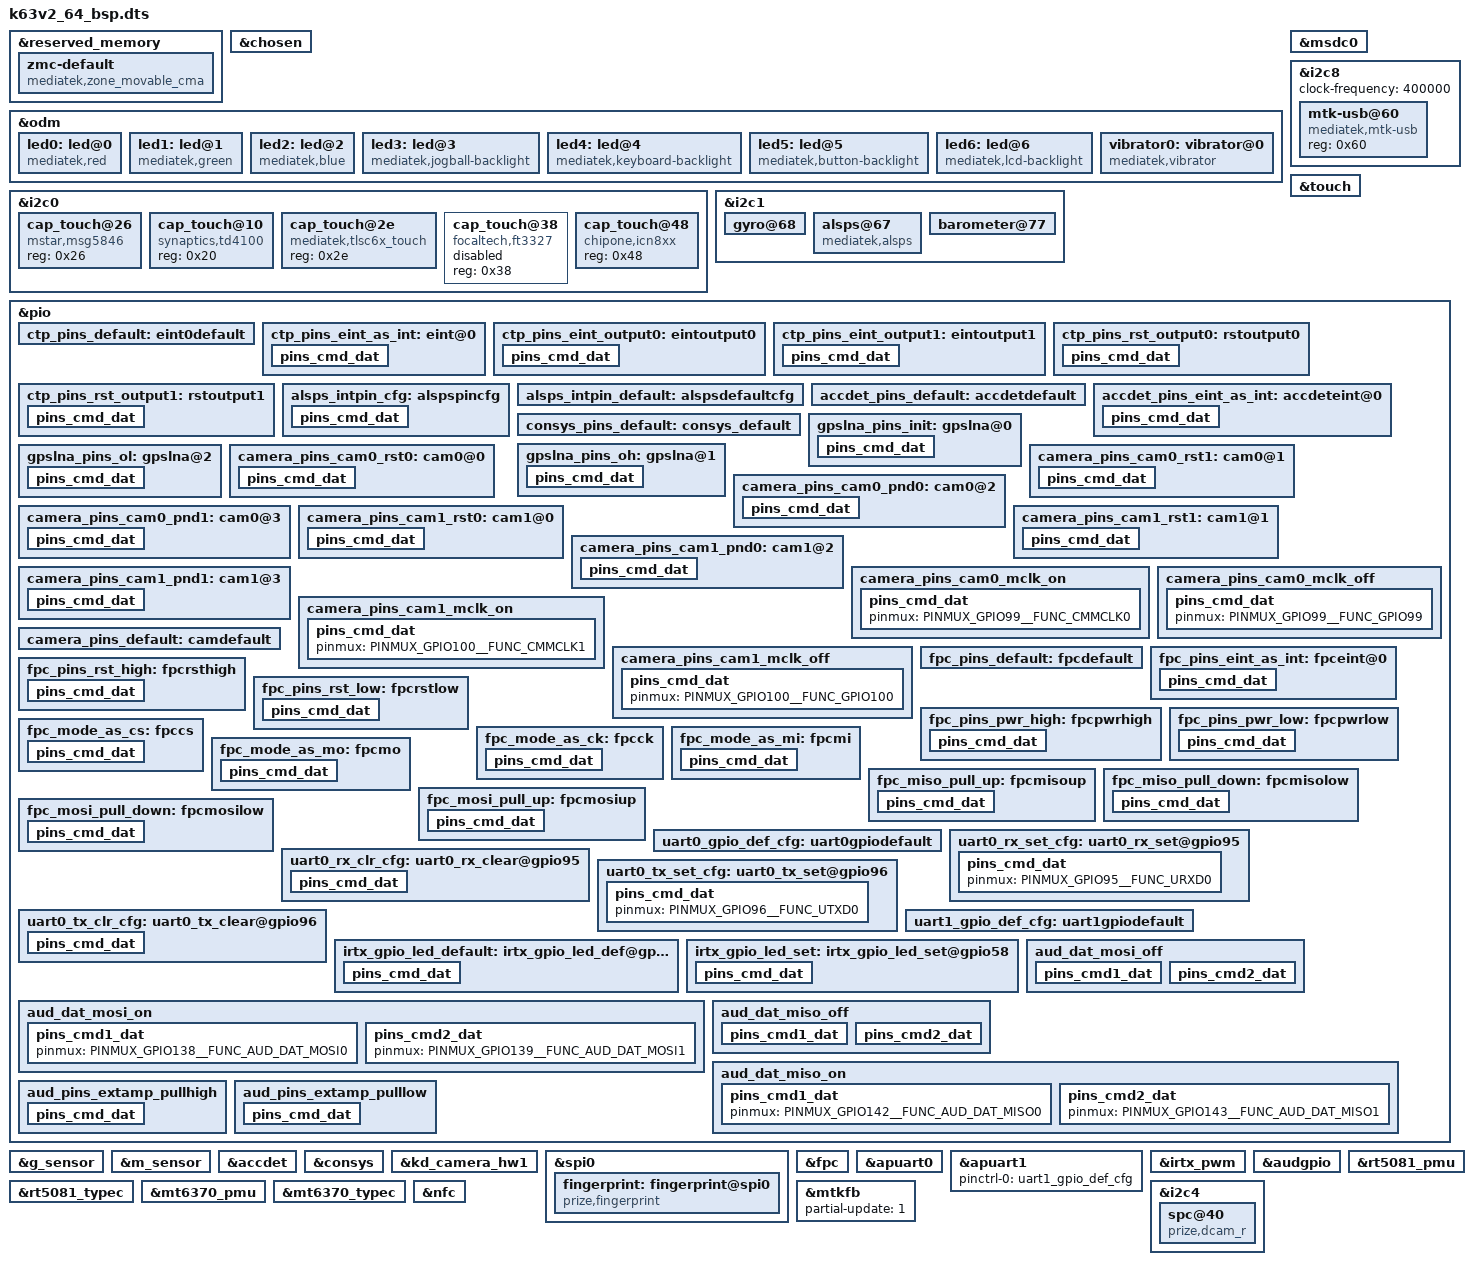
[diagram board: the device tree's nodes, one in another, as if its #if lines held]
/*
 * Mediatek's k63v2_64_bsp SoC device tree source
 *
 * Copyright (C) 2019 MediaTek Inc.
 *
 * This program is free software; you can redistribute it and/or modify
 * it under the terms of the GNU General Public License version 2 as
 * published by the Free Software Foundation.
 *
 * This program is distributed in the hope that it will be useful,
 * but WITHOUT ANY WARRANTY; without even the implied warranty of
 * MERCHANTABILITY or FITNESS FOR A PARTICULAR PURPOSE.
 * See http://www.gnu.org/licenses/gpl-2.0.html for more details.
 */
#include <generated/autoconf.h>
/dts-v1/;

#ifdef CONFIG_MTK_DTBO_FEATURE
/plugin/;
#include <dt-bindings/interrupt-controller/irq.h>
#include <dt-bindings/interrupt-controller/arm-gic.h>
#include <dt-bindings/mmc/mt6763-msdc.h>
#include <dt-bindings/pinctrl/mt6763-pinfunc.h>
#else
#include "mt6763.dts"
#endif



&reserved_memory {
	#address-cells = <2>;
	#size-cells = <2>;
	ranges;

	zmc-default {
		compatible = "mediatek,zone_movable_cma";
		size = <0 0xffc00000>;
		alignment = <0 0x10000000>;
		alloc-ranges = <0 0xc0000000 1 0x00000000>;
	};
};


/* chosen */
&chosen {
	/* fpga may has no lk, we need to specify display info here */
	/* fb buffer is reserved using this dts by memory node above */
	atag,videolfb-fb_base_h = <0x0>;
	atag,videolfb-fb_base_l = <0x5e605000>;
	atag,videolfb-islcmfound = <1>;
	/* because no lk, so lcm is not inited */
	atag,videolfb-islcm_inited = <0>;
	atag,videolfb-fps= <6000>;
	atag,videolfb-vramSize= <0x017bb000>;
	atag,videolfb-lcmname= "nt35695B_fhd_dsi_cmd_auo_rt5081_drv";
};


&odm {
	led0:led@0 {
		compatible = "mediatek,red";
		led_mode = <0>;
		data = <1>;
		pwm_config = <0 0 0 0 0>;
	};
	led1:led@1 {
		compatible = "mediatek,green";
		led_mode = <0>;
		data = <1>;
		pwm_config = <0 0 0 0 0>;
	};
	led2:led@2 {
		compatible = "mediatek,blue";
		led_mode = <0>;
		data = <1>;
		pwm_config = <0 0 0 0 0>;
	};
	led3:led@3 {
		compatible = "mediatek,jogball-backlight";
		led_mode = <0>;
		data = <1>;
		pwm_config = <0 0 0 0 0>;
	};
	led4:led@4 {
		compatible = "mediatek,keyboard-backlight";
		led_mode = <0>;
		data = <1>;
		pwm_config = <0 0 0 0 0>;
	};
	led5:led@5 {
		compatible = "mediatek,button-backlight";
		led_mode = <0>;
		data = <1>;
		pwm_config = <0 0 0 0 0>;
	};
	led6:led@6 {
		compatible = "mediatek,lcd-backlight";
		led_mode = <5>;
		data = <1>;
		pwm_config = <0 3 0 0 0>;
	};
	vibrator0:vibrator@0 {
		compatible = "mediatek,vibrator";
		vib_timer = <25>;
		vib_limit = <9>;
		vib_vol= <9>;
	};
};

&i2c0 {
	cap_touch@26 {
		compatible = "mstar,msg5846";
		reg = <0x26>;
	};
	
	cap_touch@10 {
		compatible = "synaptics,td4100";
		reg = <0x20>;
		status = "okay";
	};

    cap_touch@2e {
        compatible = "mediatek,tlsc6x_touch";
        reg = <0x2e>;  
        status = "okay";
     };
	
	cap_touch@38 {
		compatible = "focaltech,ft3327";
		reg = <0x38>;
		status = "disable"; /* focaltouch drv will auto transform addr, if mediatek,cap_touch exist disable*/
	};
	
	cap_touch@48 {
		compatible = "chipone,icn8xx";
		reg = <0x48>;
	};
	
	//cap_touch@5d {
	//	compatible = "goodix,gt9xx";
	//	reg = <0x5d>;
	//};
};
&i2c1 {
/*  start sensor */
	/*gsensor@68 {
		i2c_num	= <1>;
		direction = <4>;
		power_id = <0xffff>;
		power_vol = <0>;
		firlen = <16>;
		is_batch_supported = <1>;
	};

	msensor@0d {
		i2c_num = <1>;
		i2c_addr = <0x0d 0 0 0>;
		direction = <8>;
		power_id = <0xffff>;
		power_vol = <0>;
		is_batch_supported = <0>;
	};*/

	gyro@68 {
		i2c_num = <1>;
		i2c_addr = <0x68 0 0 0>;
		direction = <4>;
		power_id = <0xffff>;
		power_vol = <0>;
		firlen = <0>;
		is_batch_supported = <0>;
	};

	alsps@67 {
	         compatible = "mediatek,alsps";
		pinctrl-names = "pin_default", "pin_cfg";
		pinctrl-0 = <&alsps_intpin_default>;
		pinctrl-1 = <&alsps_intpin_cfg>;
		status = "okay";
		/* customization */
		i2c_num = <1>;
		i2c_addr = <0x67 0 0 0>;
		polling_mode_ps = <0>;
		polling_mode_als = <1>;
		power_id = <0xffff>;
		power_vol = <0>;
	als_level = <10 50 100 200 400 700 1000 1500 2200 3000 3500 4000 4500 5000 5500>;
	als_value = <0 50 100 200 350 600 1100 1500 2200 3000 4000 6000 8000 10000 20000 20000>;
	ps_threshold_high = <250>;
	ps_threshold_low = <100>;
	is_batch_supported_ps = <0>;
	is_batch_supported_als = <0>;

		 
		



	};

	barometer@77 {
		i2c_num = <1>;
		i2c_addr = <0x77 0 0 0>;
		direction = <0>;
		power_id = <0xffff>;
		power_vol = <0>;
		firlen = <32>;
		is_batch_supported = <0>;
	};
/* end sensor */
};

&msdc0 {
	status = "okay";
};

&i2c8 {
	#address-cells = <1>;
	#size-cells = <0>;
	clock-frequency = <400000>;

	mtk-usb@60 {
		compatible = "mediatek,mtk-usb";
		reg = <0x60>;
		status = "okay";
	};
};

/* TOUCH start */
&touch {
	tpd-resolution = <720 1520>;
	use-tpd-button = <0>;
	tpd-key-num = <3>;
	tpd-key-local= <139 172 158 0>;
	tpd-key-dim-local = <90 883 100 40 230
				 883 100 40 370 883 100 40 0 0 0 0>;
	tpd-max-touch-num = <5>;
	tpd-filter-enable = <0>;
	tpd-filter-pixel-density = <106>;
	tpd-filter-custom-prameters = <0 0 0 0 0 0 0 0 0 0 0 0>;
	tpd-filter-custom-speed = <0 0 0>;
	pinctrl-names = "default", "state_eint_as_int", "state_eint_output0",
		"state_eint_output1", "state_rst_output0", "state_rst_output1";
	pinctrl-0 = <&ctp_pins_default>;
	pinctrl-1 = <&ctp_pins_eint_as_int>;
	pinctrl-2 = <&ctp_pins_eint_output0>;
	pinctrl-3 = <&ctp_pins_eint_output1>;
	pinctrl-4 = <&ctp_pins_rst_output0>;
	pinctrl-5 = <&ctp_pins_rst_output1>;
	status = "okay";
};
&pio {
	ctp_pins_default: eint0default {
	};
	ctp_pins_eint_as_int: eint@0 {
		pins_cmd_dat {
			pinmux = <PINMUX_GPIO1__FUNC_GPIO1>;
			slew-rate = <0>;
			bias-disable;
		};
	};
	ctp_pins_eint_output0: eintoutput0 {
		pins_cmd_dat {
			pinmux = <PINMUX_GPIO1__FUNC_GPIO1>;
			slew-rate = <1>;
			output-low;
		};
	};
	ctp_pins_eint_output1: eintoutput1 {
		pins_cmd_dat {
			pinmux = <PINMUX_GPIO1__FUNC_GPIO1>;
			slew-rate = <1>;
			output-high;
		};
	};
	ctp_pins_rst_output0: rstoutput0 {
		pins_cmd_dat {
			pinmux = <PINMUX_GPIO15__FUNC_GPIO15>;
			slew-rate = <1>;
			output-low;
		};
	};
	ctp_pins_rst_output1: rstoutput1 {
		pins_cmd_dat {
			pinmux = <PINMUX_GPIO15__FUNC_GPIO15>;
			slew-rate = <1>;
			output-high;
		};
	};
};
/* TOUCH end */

&g_sensor {
	i2c_num	= <1>;
	direction = <3>;
	power_id = <0xffff>;
	power_vol = <0>;
	firlen = <16>;
	is_batch_supported = <1>;
};

&m_sensor {
	i2c_num = <1>;
	i2c_addr = <0x0c 0 0 0>;
	direction = <3>;
	power_id = <0xffff>;
	power_vol = <0>;
	is_batch_supported = <0>;
};

/* sensor gpio standization */
&pio {
	alsps_intpin_cfg: alspspincfg {

		pins_cmd_dat {
			pinmux = <PINMUX_GPIO6__FUNC_GPIO6>;
			slew-rate = <0>;
			bias-pull-up = <00>;
		};
	};

	alsps_intpin_default: alspsdefaultcfg {

	};
};
/* sensor end */

/* accdet start */
&accdet {
	/* accdet micbias voltage: 0x07,2.7v;0x05,2.5v;0x02,1.9v */
	accdet-mic-vol = <6>;
	headset-mode-setting = <0x500 0x500 1 0x1f0 0x800 0x800 0x20 0x44>;
	accdet-plugout-debounce = <1>;
	/*1:ACC mode, 2:low cost without in bias, 6:low cost with in bias*/
	accdet-mic-mode = <1>;
	/* eint_level_trigger: 8,LEVEL_LOW(default);4,LEVEL_HIGH;others,*/
	/* LEVEL_LOW */
	headset-eint-level-pol = <8>;
	/*0--MD_MAX--UP_MAX--DW_MAX*/
	headset-three-key-threshold = <0 80 200 400>;
	headset-three-key-threshold-CDD = <0 121 192 600>;
	/*0--MD_MAX--VOICE_MAX--UP_MAX--DW_MAX*/
	headset-four-key-threshold = <0 58 121 192 400>;
	/* ACCDET GPIO standardization ACC mode no use */
	/* interrupt-parent = <&eintc>; */
	/* interrupts = <9 IRQ_TYPE_EDGE_FALLING 9 0>;	*/
	pinctrl-names = "default", "state_eint_as_int";
	pinctrl-0 = <&accdet_pins_default>;
	pinctrl-1 = <&accdet_pins_eint_as_int>;
	status = "okay";
};
&pio {
	accdet_pins_default: accdetdefault {
	};
	accdet_pins_eint_as_int: accdeteint@0 {
		pins_cmd_dat {
			pinmux = <PINMUX_GPIO9__FUNC_GPIO9>;
			slew-rate = <0>;
			bias-disable;
		};
	};
};
/* accdet end */

/* CONSYS GPIO standardization */
&pio {
	consys_pins_default: consys_default {
	};
	gpslna_pins_init: gpslna@0 {
		pins_cmd_dat {
			pinmux = <PINMUX_GPIO107__FUNC_GPIO107>;
			slew-rate = <0>;
			bias-disable;
			output-low;
		};
	};
	gpslna_pins_oh: gpslna@1 {
		pins_cmd_dat {
			pinmux = <PINMUX_GPIO107__FUNC_GPIO107>;
			slew-rate = <1>;
			output-high;
		};
	};
	gpslna_pins_ol: gpslna@2 {
		pins_cmd_dat {
			pinmux = <PINMUX_GPIO107__FUNC_GPIO107>;
			slew-rate = <1>;
			output-low;
		};
	};
};
&consys {
	pinctrl-names = "default", "gps_lna_state_init", "gps_lna_state_oh",
			"gps_lna_state_ol";
	pinctrl-0 = <&consys_pins_default>;
	pinctrl-1 = <&gpslna_pins_init>;
	pinctrl-2 = <&gpslna_pins_oh>;
	pinctrl-3 = <&gpslna_pins_ol>;
	status = "okay";
};
/* CONSYS end */

 /* CAMERA GPIO standardization */
&pio {
	camera_pins_cam0_rst0: cam0@0 {
		pins_cmd_dat {
			pinmux = <PINMUX_GPIO101__FUNC_GPIO101>;
			slew-rate = <1>; /*direction 0:in, 1:out*/
			/*direction out used only. output_low or high*/
			output-low;
		};
	};
	camera_pins_cam0_rst1: cam0@1 {
		pins_cmd_dat {
			pinmux = <PINMUX_GPIO101__FUNC_GPIO101>;
			slew-rate = <1>;
			output-high;
		};
	};
	camera_pins_cam0_pnd0: cam0@2 {
		pins_cmd_dat {
			pinmux = <PINMUX_GPIO97__FUNC_GPIO97>;
			slew-rate = <1>;
			output-low;
		};
	};
	camera_pins_cam0_pnd1: cam0@3 {
		pins_cmd_dat {
			pinmux = <PINMUX_GPIO97__FUNC_GPIO97>;
			slew-rate = <1>;
			output-high;
		};
	};
	camera_pins_cam1_rst0: cam1@0 {
		pins_cmd_dat {
			pinmux = <PINMUX_GPIO102__FUNC_GPIO102>;
			slew-rate = <1>; /*direction 0:in, 1:out*/
			/*direction out used only.output_low or high*/
			output-low;
		};
	};
	camera_pins_cam1_rst1: cam1@1 {
		pins_cmd_dat {
			pinmux = <PINMUX_GPIO102__FUNC_GPIO102>;
			slew-rate = <1>;
			output-high;
		};
	};
	camera_pins_cam1_pnd0: cam1@2 {
		pins_cmd_dat {
			pinmux = <PINMUX_GPIO98__FUNC_GPIO98>;
			slew-rate = <1>;
			output-low;
		};
	};
	camera_pins_cam1_pnd1: cam1@3 {
		pins_cmd_dat {
			pinmux = <PINMUX_GPIO98__FUNC_GPIO98>;
			slew-rate = <1>;
			output-high;
		};
	};
	camera_pins_cam0_mclk_on: camera_pins_cam0_mclk_on {
		pins_cmd_dat {
			pinmux = <PINMUX_GPIO99__FUNC_CMMCLK0>;
		};
	};
	camera_pins_cam0_mclk_off: camera_pins_cam0_mclk_off {
		pins_cmd_dat {
			pinmux = <PINMUX_GPIO99__FUNC_GPIO99>;
		};
	};
	camera_pins_cam1_mclk_on: camera_pins_cam1_mclk_on {
		pins_cmd_dat {
			pinmux = <PINMUX_GPIO100__FUNC_CMMCLK1>;
		};
	};
	camera_pins_cam1_mclk_off: camera_pins_cam1_mclk_off {
		pins_cmd_dat {
			pinmux = <PINMUX_GPIO100__FUNC_GPIO100>;
		};
	};
	camera_pins_default: camdefault {
	};

};

&kd_camera_hw1 {
	pinctrl-names = "default",
			"cam0_rst0", "cam0_rst1", "cam0_pnd0", "cam0_pnd1",
			"cam1_rst0", "cam1_rst1", "cam1_pnd0", "cam1_pnd1",
			"cam0_mclk_on", "cam0_mclk_off",
			"cam1_mclk_on", "cam1_mclk_off";

	pinctrl-0 = <&camera_pins_default>;
	pinctrl-1 = <&camera_pins_cam0_rst0>;
	pinctrl-2 = <&camera_pins_cam0_rst1>;
	pinctrl-3 = <&camera_pins_cam0_pnd0>;
	pinctrl-4 = <&camera_pins_cam0_pnd1>;
	pinctrl-5 = <&camera_pins_cam1_rst0>;
	pinctrl-6 = <&camera_pins_cam1_rst1>;
	pinctrl-7 = <&camera_pins_cam1_pnd0>;
	pinctrl-8 = <&camera_pins_cam1_pnd1>;
	pinctrl-13 = <&camera_pins_cam0_mclk_on>;
	pinctrl-14 = <&camera_pins_cam0_mclk_off>;
	pinctrl-15 = <&camera_pins_cam1_mclk_on>;
	pinctrl-16 = <&camera_pins_cam1_mclk_off>;
	status = "okay";

};
/* CAMERA GPIO end */

/* prize-wyq 20190412 add for sunwave fingerprint-start */
/* Fingerprint GPIO standardization */
&spi0{
	#address-cells = <1>;
	#size-cells = <0>;
	fingerprint: fingerprint@spi0{
		compatible = "prize,fingerprint";
		reg = <0>;
		spi-max-frequency = <1000000>;
		/*other infromation*/
		/*spi-cpha;*/    /*set cpha=1, optional*/
		/*spi-cpol;*/    /*set cpol=1, optional*/
		/*spi-cs-high;*/    /*set cs active level=1, optional*/
		/*spi-3wire;*/    /*set no-tx or no-rx, optional*/
		/*spi-lsb-first;*/    /*set lsb-first transfer, optional*/
		fingerprint,touch-int-gpio = <&pio 8 0>;
		status = "okay";
	};
};

&fpc {
	interrupt-parent = <&pio>;
	interrupts = <8 IRQ_TYPE_EDGE_FALLING 8 0>;	
	pinctrl-names = "default",
		"fpc_eint_as_int",
		"fpc_pins_rst_high", "fpc_pins_rst_low",
		"fpc_pins_pwr_high", "fpc_pins_pwr_low",
		"fpc_mode_as_cs", "fpc_mode_as_ck",
		"fpc_mode_as_mi", "fpc_mode_as_mo",
		"fpc_miso_pull_up", "fpc_miso_pull_down",
		"fpc_mosi_pull_up", "fpc_mosi_pull_down";
	pinctrl-0 = <&fpc_pins_default>;
	pinctrl-1 = <&fpc_pins_eint_as_int>;
	pinctrl-2 = <&fpc_pins_rst_high>;
	pinctrl-3 = <&fpc_pins_rst_low>;
	pinctrl-4 = <&fpc_pins_pwr_high>;
	pinctrl-5 = <&fpc_pins_pwr_low>;
	pinctrl-6 = <&fpc_mode_as_cs>;
	pinctrl-7 = <&fpc_mode_as_ck>;
	pinctrl-8= <&fpc_mode_as_mi>;
	pinctrl-9 = <&fpc_mode_as_mo>;
	pinctrl-10 = <&fpc_miso_pull_up>;
	pinctrl-11 = <&fpc_miso_pull_down>;
	pinctrl-12 = <&fpc_mosi_pull_up>;
	pinctrl-13 = <&fpc_mosi_pull_down>;
	status = "okay";
};

&pio {
	fpc_pins_default: fpcdefault {
	};

	fpc_pins_eint_as_int: fpceint@0 {
		pins_cmd_dat {
			pinmux = <PINMUX_GPIO8__FUNC_GPIO8>;
			slew-rate = <0>;
			bias-disable;
		};
	};
	fpc_pins_rst_high: fpcrsthigh {
		pins_cmd_dat {
			pinmux = <PINMUX_GPIO18__FUNC_GPIO18>;
			slew-rate = <1>;
			output-high;
		};
	};
	fpc_pins_rst_low: fpcrstlow {
		pins_cmd_dat {
			pinmux = <PINMUX_GPIO18__FUNC_GPIO18>;
			slew-rate = <1>;
			output-low;
		};
	};
	fpc_pins_pwr_high: fpcpwrhigh {
		pins_cmd_dat {
			pinmux = <PINMUX_GPIO80__FUNC_GPIO80>;
			slew-rate = <1>;
			output-high;
		};
	};
	fpc_pins_pwr_low: fpcpwrlow {
		pins_cmd_dat {
			pinmux = <PINMUX_GPIO80__FUNC_GPIO80>;
			slew-rate = <1>;
			output-low;
		};
	};	
	fpc_mode_as_cs: fpccs {
		pins_cmd_dat {
			pinmux = <PINMUX_GPIO86__FUNC_SPI0_CSB>;
			bias-pull-up = <00>;
		};
	};
	fpc_mode_as_ck: fpcck {
		pins_cmd_dat {
			pinmux = <PINMUX_GPIO88__FUNC_SPI0_CLK>;
			bias-pull-up = <00>;
		};
	};
	fpc_mode_as_mi: fpcmi {
		pins_cmd_dat {
			pinmux = <PINMUX_GPIO85__FUNC_SPI0_MI>;
			bias-pull-up = <00>;
		};
	};
	fpc_mode_as_mo: fpcmo {
		pins_cmd_dat {
			pinmux = <PINMUX_GPIO87__FUNC_SPI0_MO>;
			bias-pull-down = <00>;
		};
	};
	fpc_miso_pull_up: fpcmisoup {
		pins_cmd_dat {
			pinmux = <PINMUX_GPIO85__FUNC_GPIO85>;
			slew-rate = <1>;
			output-high;
		};
	};
	fpc_miso_pull_down: fpcmisolow {
		pins_cmd_dat {
			pinmux = <PINMUX_GPIO85__FUNC_GPIO85>;
			slew-rate = <1>;
			output-low;
		};
	};
	fpc_mosi_pull_up: fpcmosiup {
		pins_cmd_dat {
			pinmux = <PINMUX_GPIO87__FUNC_GPIO87>;
			slew-rate = <1>;
			output-high;
		};
	};
	fpc_mosi_pull_down: fpcmosilow {
		pins_cmd_dat {
			pinmux = <PINMUX_GPIO87__FUNC_GPIO87>;
			slew-rate = <1>;
			output-low;
		};
	};
};
/*add by lipengpeng  Fingerprint GPIO end */

/* UART GPIO */
&apuart0 {
	pinctrl-names = "uart0_gpio_default",
			"uart0_rx_set",
			"uart0_rx_clear",
			"uart0_tx_set",
			"uart0_tx_clear";
	pinctrl-0 = <&uart0_gpio_def_cfg>;
	pinctrl-1 = <&uart0_rx_set_cfg>;
	pinctrl-2 = <&uart0_rx_clr_cfg>;
	pinctrl-3 = <&uart0_tx_set_cfg>;
	pinctrl-4 = <&uart0_tx_clr_cfg>;
	status = "okay";
};

&apuart1 {
	pinctrl-names = "uart1_gpio_default";
	pinctrl-0 = <&uart1_gpio_def_cfg>;
	status = "okay";
};

&pio {
	/* UART GPIO Settings - Start */
	/* UART0: rx set, rx clear, tx clear, tx clear*/
	uart0_gpio_def_cfg:uart0gpiodefault {

	};
	uart0_rx_set_cfg:uart0_rx_set@gpio95 {
		pins_cmd_dat {
			pinmux = <PINMUX_GPIO95__FUNC_URXD0>;
		};
	};
	uart0_rx_clr_cfg:uart0_rx_clear@gpio95 {
		pins_cmd_dat {
			pinmux = <PINMUX_GPIO95__FUNC_GPIO95>;
			slew-rate = <1>;
			output-high;
		};
	};
	uart0_tx_set_cfg:uart0_tx_set@gpio96 {
		pins_cmd_dat {
			pinmux = <PINMUX_GPIO96__FUNC_UTXD0>;
		};
	};
	uart0_tx_clr_cfg:uart0_tx_clear@gpio96 {
		pins_cmd_dat {
			pinmux = <PINMUX_GPIO96__FUNC_GPIO96>;
			slew-rate = <1>;
			output-high;
		};
	};
	/* UART1:GPIO default setting*/
	uart1_gpio_def_cfg:uart1gpiodefault {

	};
};/* UART GPIO end */

/* IRTX GPIO end */
&irtx_pwm {
	pinctrl-names = "irtx_gpio_led_default", "irtx_gpio_led_set";
	pinctrl-0 = <&irtx_gpio_led_default>;
	pinctrl-1 = <&irtx_gpio_led_set>;
	status = "okay";
};
&pio {
	/* IRTX GPIO Settings -Start */
	/* default: GPIO0, output, high */
	irtx_gpio_led_default:irtx_gpio_led_def@gpio58 {
		pins_cmd_dat {
			pinmux = <PINMUX_GPIO58__FUNC_GPIO58>;
			slew-rate = <1>;
			bias-disable;
			output-low;
			input-schmitt-enable = <0>;
		};
	};

	irtx_gpio_led_set:irtx_gpio_led_set@gpio58 {
		pins_cmd_dat {
			pinmux = <PINMUX_GPIO58__FUNC_PWM_B>;
			slew-rate = <1>;
			output-high;
		};
	};
}; /* IRTX GPIO Settings -End */

/* AUDIO GPIO standardization */
&audgpio {
	pinctrl-names = "aud_dat_mosi_off",
			"aud_dat_mosi_on",
			"aud_dat_miso_off",
			"aud_dat_miso_on",
			"extamp-pullhigh",
			"extamp-pulllow";
	pinctrl-0 = <&aud_dat_mosi_off>;
	pinctrl-1 = <&aud_dat_mosi_on>;
	pinctrl-2 = <&aud_dat_miso_off>;
	pinctrl-3 = <&aud_dat_miso_on>;
	pinctrl-4 = <&aud_pins_extamp_pullhigh>;
	pinctrl-5 = <&aud_pins_extamp_pulllow>;
	status = "okay";
};

&pio {
	aud_dat_mosi_off: aud_dat_mosi_off {
		pins_cmd1_dat {
			pinmux = <PINMUX_GPIO138__FUNC_GPIO138>;
			input-enable;
			slew-rate = <0>;
			bias-disable;
		};
		pins_cmd2_dat {
			pinmux = <PINMUX_GPIO139__FUNC_GPIO139>;
			input-enable;
			slew-rate = <0>;
			bias-disable;
		};
	};

	aud_dat_mosi_on: aud_dat_mosi_on {
		pins_cmd1_dat {
			pinmux = <PINMUX_GPIO138__FUNC_AUD_DAT_MOSI0>;
		};
		pins_cmd2_dat {
			pinmux = <PINMUX_GPIO139__FUNC_AUD_DAT_MOSI1>;
		};
	};

	aud_dat_miso_off: aud_dat_miso_off {
		pins_cmd1_dat {
			pinmux = <PINMUX_GPIO142__FUNC_GPIO142>;
			input-enable;
			slew-rate = <0>;
			bias-disable;
		};
		pins_cmd2_dat {
			pinmux = <PINMUX_GPIO143__FUNC_GPIO143>;
			input-enable;
			slew-rate = <0>;
			bias-disable;
		};
	};

	aud_dat_miso_on: aud_dat_miso_on {
		pins_cmd1_dat {
			pinmux = <PINMUX_GPIO142__FUNC_AUD_DAT_MISO0>;
		};
		pins_cmd2_dat {
			pinmux = <PINMUX_GPIO143__FUNC_AUD_DAT_MISO1>;
		};
	};

	aud_pins_extamp_pullhigh: aud_pins_extamp_pullhigh {
		pins_cmd_dat {
			pinmux = <PINMUX_GPIO19__FUNC_GPIO19>;
			slew-rate = <1>;
			output-high;
		};
	};

	aud_pins_extamp_pulllow: aud_pins_extamp_pulllow {
		pins_cmd_dat {
			pinmux = <PINMUX_GPIO19__FUNC_GPIO19>;
			slew-rate = <1>;
			output-low;
		};
	};
};
/* AUDIO end */

#ifdef CONFIG_MFD_RT5081_PMU
&rt5081_pmu {
	rt,intr_gpio_num = <91>; /* direct defined GPIO num */
	rt,intr_gpio = <&pio 91 0x0>;
};
#endif
#ifdef CONFIG_TCPC_RT5081
&rt5081_typec {
	rt5081pd,intr_gpio_num = <41>; /* direct defined GPIO num */
	rt5081pd,intr_gpio = <&pio 41 0x0>;
};
#endif
#ifdef CONFIG_MFD_MT6370_PMU
&mt6370_pmu {
	mt6370,intr_gpio_num = <91>; /* direct defined GPIO num */
	mt6370,intr_gpio = <&pio 91 0x0>;
};
#endif
#ifdef CONFIG_TCPC_MT6370
&mt6370_typec {
	mt6370pd,intr_gpio_num = <41>; /* direct defined GPIO num */
	mt6370pd,intr_gpio = <&pio 41 0x0>;
};
#endif


&nfc {
	gpio-rst = <25>;
	gpio-rst-std = <&pio 25 0x0>;
	gpio-irq = <0>;
	gpio-irq-std = <&pio 0  0x0>;
};

&mtkfb {
	partial-update = <1>;
	status = "okay";
};


/*zhengjiang.zhu@Koobee.Camera.Driver  2018/11/2  add for prize double camera gc6133*/
&i2c4 {
	spc@40 {
		compatible = "prize,dcam_r";
		reg = <0x40>;
		pdn_pin = <&pio 54 0>;
		rst_pin = <&pio 78 0>;
		sensor_type = <6133>;	/*DO NOT write 0310*/
	};
};
/*zhengjiang.zhu@Koobee.Camera.Driver  2018/11/2  end for prize double camera gc6133*/
#include <k63v2_64_bsp/cust.dtsi>
/*End of this file, DO NOT ADD ANYTHING HERE*/
